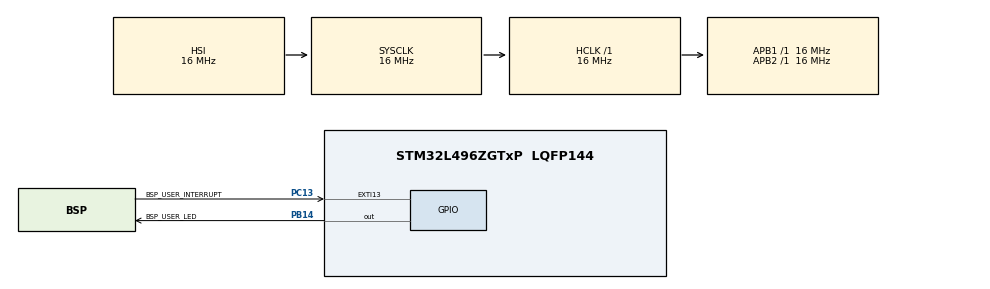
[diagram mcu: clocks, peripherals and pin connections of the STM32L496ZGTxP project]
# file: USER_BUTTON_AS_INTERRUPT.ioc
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Mcu.Family=STM32L4
Mcu.Name=STM32L496ZGTxP
Mcu.Package=LQFP144
NVIC.EXTI15_10_IRQn=true\:0\:0\:false\:false\:true\:true\:true\:true
NVIC.PriorityGroup=NVIC_PRIORITYGROUP_4
PB14.GPIO_Label=BSP_USER_LED
PB14.Signal=GPIO_Output
PC13.GPIO_Label=BSP_USER_INTERRUPT
PC13.GPIO_ModeDefaultEXTI=GPIO_MODE_IT_FALLING
PC13.GPIO_PuPd=GPIO_NOPULL
PC13.Signal=GPXTI13
PC14-OSC32_IN\ (PC14).Mode=LSE-External-Oscillator
PC14-OSC32_IN\ (PC14).Signal=RCC_OSC32_IN
PC15-OSC32_OUT\ (PC15).Mode=LSE-External-Oscillator
PC15-OSC32_OUT\ (PC15).Signal=RCC_OSC32_OUT
PH0-OSC_IN\ (PH0).Mode=HSE-External-Clock-Source
PH0-OSC_IN\ (PH0).Signal=RCC_OSC_IN
ProjectManager.HeapSize=0x200
ProjectManager.StackSize=0x400
ProjectManager.TargetToolchain=STM32CubeIDE
RCC.48MHZClocksFreq_Value=24000000
RCC.AHBFreq_Value=16000000
RCC.APB1Freq_Value=16000000
RCC.APB1TimFreq_Value=16000000
RCC.APB2Freq_Value=16000000
RCC.APB2TimFreq_Value=16000000
RCC.CortexFreq_Value=16000000
RCC.HCLKFreq_Value=16000000
RCC.HSE_VALUE=8000000
RCC.HSI48_VALUE=48000000
RCC.HSI_VALUE=16000000
RCC.MSI_VALUE=4000000
RCC.PLLMUL=RCC_PLL_MUL9
RCC.PRESCALERUSB=RCC_USBCLKSOURCE_PLL_DIV1_5
RCC.SYSCLKFreq_VALUE=16000000
RCC.SYSCLKSource=RCC_SYSCLKSOURCE_HSI
RCC.SYSCLKSourceVirtual=RCC_SYSCLKSOURCE_PLLCLK
RCC.USBFreq_Value=16000000
RCC.VCOOutputFreq_Value=32000000
board=NUCLEO-L496ZG-P

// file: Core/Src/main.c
/* USER CODE BEGIN Header */
/**
  ******************************************************************************
  * @file           : main.c
  * @brief          : Main program body
  ******************************************************************************
  * @attention
  *
  * Copyright (c) 2024 STMicroelectronics.
  * All rights reserved.
  *
  * This software is licensed under terms that can be found in the LICENSE file
  * in the root directory of this software component.
  * If no LICENSE file comes with this software, it is provided AS-IS.
  *
  ******************************************************************************
  */
/* USER CODE END Header */
#include "main.h"

/* USER CODE BEGIN Includes */
#include "stdbool.h"
/* USER CODE END Includes */

/* USER CODE BEGIN PM */
#define ENABLE 1
/* USER CODE END PM */

/* USER CODE BEGIN PV */
	static volatile bool isbutton_press = false;
 static bool led_status = false;
/* USER CODE END PV */

void SystemClock_Config(void);
static void MX_GPIO_Init(void);
/* USER CODE BEGIN PFP */
void HAL_GPIO_EXTI_Callback(uint16_t GPIO_Pin);
void my_delay();
/* USER CODE END PFP */

int main(void)
{

  /* MCU Configuration--------------------------------------------------------*/

  /* Reset of all peripherals, Initializes the Flash interface and the Systick. */
  HAL_Init();

  /* Configure the system clock */
  SystemClock_Config();

  /* Initialize all configured peripherals */
  MX_GPIO_Init();

  /* Infinite loop */
  while (1)
  {

    /* USER CODE BEGIN 3 */

	  if(isbutton_press == true)		//check if button is pressed pr not
	  {
		  if(led_status == false)		//check if led is on or off
		  {
			  //if led is off, on the led
			  HAL_GPIO_WritePin(BSP_USER_LED_GPIO_Port, BSP_USER_LED_Pin, GPIO_PIN_SET);
		  	  HAL_Delay(500);	//delay is for avoiding the debouncing issue
		  	led_status = true;
		  }
		  else
		  {
			  //if led is on, off the led
		  	  HAL_GPIO_WritePin(BSP_USER_LED_GPIO_Port, BSP_USER_LED_Pin, GPIO_PIN_RESET);
		  	  HAL_Delay(500);	//delay is for avoiding the debouncing issue
		  	led_status = false;
		  }
		  isbutton_press = false;		//change the state of button for next state
	  }

//	  if(flag == true)
//	  {
//		  HAL_GPIO_TogglePin(BSP_USER_LED_GPIO_Port, BSP_USER_LED_Pin);
//		  HAL_Delay(250);
//		  flag = false;
//	  }
  }
  /* USER CODE END 3 */
}

void SystemClock_Config(void)
{
  RCC_OscInitTypeDef RCC_OscInitStruct = {0};
  RCC_ClkInitTypeDef RCC_ClkInitStruct = {0};

  /** Configure the main internal regulator output voltage
  */
  if (HAL_PWREx_ControlVoltageScaling(PWR_REGULATOR_VOLTAGE_SCALE1) != HAL_OK)
  {
    Error_Handler();
  }

  /** Initializes the RCC Oscillators according to the specified parameters
  * in the RCC_OscInitTypeDef structure.
  */
  RCC_OscInitStruct.OscillatorType = RCC_OSCILLATORTYPE_HSI;
  RCC_OscInitStruct.HSIState = RCC_HSI_ON;
  RCC_OscInitStruct.HSICalibrationValue = RCC_HSICALIBRATION_DEFAULT;
  RCC_OscInitStruct.PLL.PLLState = RCC_PLL_NONE;
  if (HAL_RCC_OscConfig(&RCC_OscInitStruct) != HAL_OK)
  {
    Error_Handler();
  }

  /** Initializes the CPU, AHB and APB buses clocks
  */
  RCC_ClkInitStruct.ClockType = RCC_CLOCKTYPE_HCLK|RCC_CLOCKTYPE_SYSCLK
                              |RCC_CLOCKTYPE_PCLK1|RCC_CLOCKTYPE_PCLK2;
  RCC_ClkInitStruct.SYSCLKSource = RCC_SYSCLKSOURCE_HSI;
  RCC_ClkInitStruct.AHBCLKDivider = RCC_SYSCLK_DIV1;
  RCC_ClkInitStruct.APB1CLKDivider = RCC_HCLK_DIV1;
  RCC_ClkInitStruct.APB2CLKDivider = RCC_HCLK_DIV1;

  if (HAL_RCC_ClockConfig(&RCC_ClkInitStruct, FLASH_LATENCY_0) != HAL_OK)
  {
    Error_Handler();
  }
}

static void MX_GPIO_Init(void)
{
  GPIO_InitTypeDef GPIO_InitStruct = {0};

  /* GPIO Ports Clock Enable */
  __HAL_RCC_GPIOC_CLK_ENABLE();
  __HAL_RCC_GPIOH_CLK_ENABLE();
  __HAL_RCC_GPIOB_CLK_ENABLE();

  /*Configure GPIO pin Output Level */
  HAL_GPIO_WritePin(BSP_USER_LED_GPIO_Port, BSP_USER_LED_Pin, GPIO_PIN_RESET);

  /*Configure GPIO pin : BSP_USER_INTERRUPT_Pin */
  GPIO_InitStruct.Pin = BSP_USER_INTERRUPT_Pin;
  GPIO_InitStruct.Mode = GPIO_MODE_IT_FALLING;
  GPIO_InitStruct.Pull = GPIO_NOPULL;
  HAL_GPIO_Init(BSP_USER_INTERRUPT_GPIO_Port, &GPIO_InitStruct);

  /*Configure GPIO pin : BSP_USER_LED_Pin */
  GPIO_InitStruct.Pin = BSP_USER_LED_Pin;
  GPIO_InitStruct.Mode = GPIO_MODE_OUTPUT_PP;
  GPIO_InitStruct.Pull = GPIO_NOPULL;
  GPIO_InitStruct.Speed = GPIO_SPEED_FREQ_LOW;
  HAL_GPIO_Init(BSP_USER_LED_GPIO_Port, &GPIO_InitStruct);

  /* EXTI interrupt init*/
  HAL_NVIC_SetPriority(EXTI15_10_IRQn, 0, 0);
  HAL_NVIC_EnableIRQ(EXTI15_10_IRQn);

}

/* USER CODE BEGIN 4 */
void HAL_GPIO_EXTI_Callback(uint16_t GPIO_Pin)
{
	 if(GPIO_Pin == BSP_USER_INTERRUPT_Pin)
	 {
		 isbutton_press = true;		//if button is pressed then this flag is true
	 }
}

/* USER CODE END 4 */

void Error_Handler(void)
{
  __disable_irq();
  while (1)
  {
  }
}
